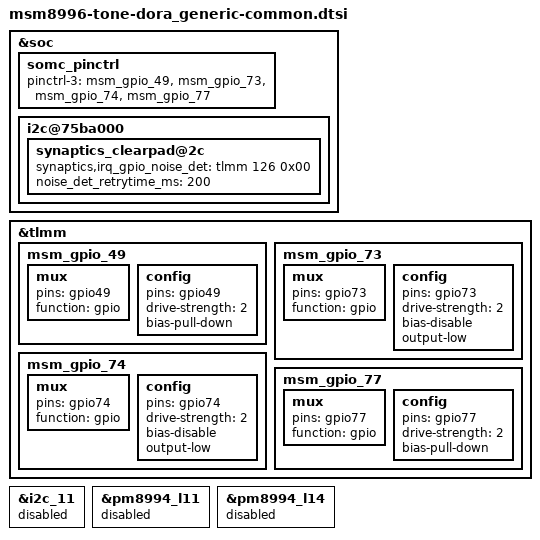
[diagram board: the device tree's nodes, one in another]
/* arch/arm/boot/dts/qcom/msm8996-tone-dora_generic-common.dtsi
 *
 * This program is free software; you can redistribute it and/or modify
 * it under the terms of the GNU General Public License version 2 and
 * only version 2 as published by the Free Software Foundation.
 *
 * This program is distributed in the hope that it will be useful,
 * but WITHOUT ANY WARRANTY; without even the implied warranty of
 * MERCHANTABILITY or FITNESS FOR A PARTICULAR PURPOSE.  See the
 * GNU General Public License for more details.
 */
/*
 * Copyright (C) 2015 Sony Mobile Communications Inc.
 *
 * This program is free software; you can redistribute it and/or modify
 * it under the terms of the GNU General Public License version 2, as
 * published by the Free Software Foundation.
 */

&soc {
	somc_pinctrl: somc_pinctrl {
		/* If variant specific default setting is needed,
		   fill pinctrl-3 value in <variant>.dtsi */
		pinctrl-3 = <&msm_gpio_49 &msm_gpio_73 &msm_gpio_74
				&msm_gpio_77>;
	};

	/* I2C : BLSP12 */
	i2c@75ba000 {
		synaptics_clearpad@2c {
			synaptics,irq_gpio_noise_det = <&tlmm 126 0x00>;
			noise_det_retrytime_ms = <200>;
		};
	};
};

&tlmm {
	/* GPIO_49 : NC */
	msm_gpio_49: msm_gpio_49 {
		mux {
			pins = "gpio49";
			function = "gpio";
		};

		config {
			pins = "gpio49";
			drive-strength = <2>;
			/delete-property/ bias-pull-up;
			bias-pull-down;
		};
	};

	/* GPIO_73 : NC */
	msm_gpio_73: msm_gpio_73 {
		mux {
			pins = "gpio73";
			function = "gpio";
		};

		config {
			pins = "gpio73";
			drive-strength = <2>;
			bias-disable;
			output-low;
		};
	};

	/* GPIO_74 : NC */
	msm_gpio_74: msm_gpio_74 {
		mux {
			pins = "gpio74";
			function = "gpio";
		};

		config {
			pins = "gpio74";
			drive-strength = <2>;
			bias-disable;
			output-low;
		};
	};

	/* GPIO_77 : NC */
	msm_gpio_77: msm_gpio_77 {
		mux {
			pins = "gpio77";
			function = "gpio";
		};

		config {
			pins = "gpio77";
			drive-strength = <2>;
			bias-pull-down;
		};
	};
};

/* I2C : BLSP11 */
&i2c_11 {
	status = "disabled";
};

/* Regulator config */
&pm8994_l11 {
	status = "disabled";
};

&pm8994_l14 {
	status = "disabled";
};
